# GPU0_PBIST_CFG register map
Vendor: Texas Instruments
Peripheral module from a debugger description file (folder J7ES).
Registers are 32-bit, read-write, reset 0x0 unless marked. A register's access mark holds for its fields unless they carry their own. Offsets are as the file gives them; lines under a group give offsets from that group; [hi:lo] are bit positions; {n}, {i} and the like mark numbered series; 'fields as' and 'values as' point back to an identical list; <NAME> marks a mode.

## GPU0_PBIST_CFG
{0x100+4i} GPU0_A{i} (i=0..3) — Return to the . Variable Address Registers
  [15:0] A{i} — Variable Address Register {i} (
{0x110+4i} GPU0_L{i} (i=0..3) — Return to the . Variable Loop Count Registers
  [15:0] L{i} — Variable Loop Count Register {i} (
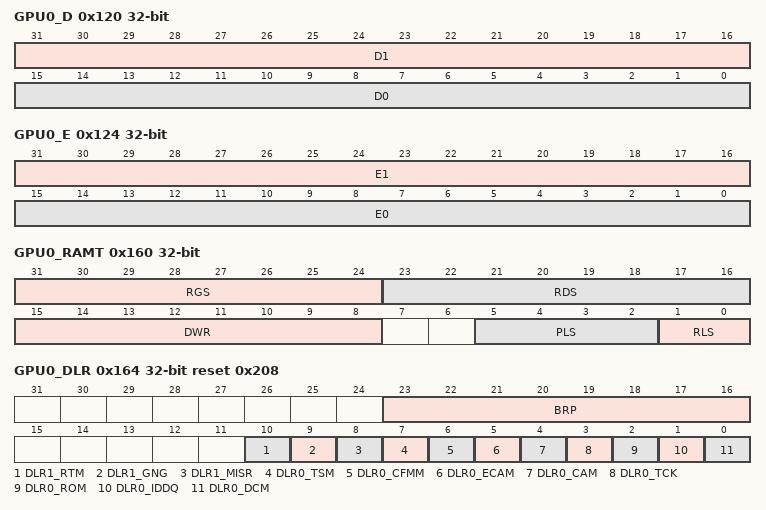
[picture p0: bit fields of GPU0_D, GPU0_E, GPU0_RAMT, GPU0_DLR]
0x120 GPU0_D — Return to the . Data Registers
  [31:16] D1 — DD1 Data Register Upper 16 (D1)
  [15:0] D0 — DD0 Data Register Lower 16 (D0)
0x124 GPU0_E — Return to the . Data Registers
  [31:16] E1 — EE1 Data Register Upper 16 (E1)
  [15:0] E0 — EE0 Data Register Lower 16 (E0)
{0x130+4i} GPU0_CA{i} (i=0..3) — Return to the . Constant Address Registers
  [15:0] CA{i} — Constant Address Register {i} (
{0x140+4i} GPU0_CL{i} (i=0..3) — Return to the . Constant Loop Count Registers
  [15:0] CL{i} — Constant Loop Count Register {i} (
{0x150+4i} GPU0_I{i} (i=0..3) — Return to the . Constant Increment Registers
  [15:0] I0 — Constant Increment Register {i} (
0x160 GPU0_RAMT — Return to the . RAM Configuration Register
  [31:24] RGS — RAM Group Select RGS
  [23:16] RDS — Return Data select RDS
  [15:8] DWR — Data Width Register DWR
  [5:2] PLS — Pipeline Latency Select
  [1:0] RLS — RAM Latency Select
0x164 GPU0_DLR reset 0x208 — Return to the . Datalogger Register
  [23:16] BRP — Datalogger 2 (BRP)
  [10] DLR1_RTM — Retention testing mode
  [9] DLR1_GNG — GO / NO-GO testing mode
  [8] DLR1_MISR — MISR testing mode (mainly for
  [7] DLR0_TSM — Time stamp mode
  [6] DLR0_CFMM — Column Fail Masking mode
  [5] DLR0_ECAM — Emulation cache access mode
  [4] DLR0_CAM — Config access mode
  [3] DLR0_TCK — TCK Gated mode
  [2] DLR0_ROM
  [1] DLR0_IDDQ — IDDQ testing mode
  [0] DLR0_DCM — Distributed Compare mode
0x168 GPU0_CMS — Return to the . Clock-Mux Select Register
  [3:0] CMS — Clock Mux Select (
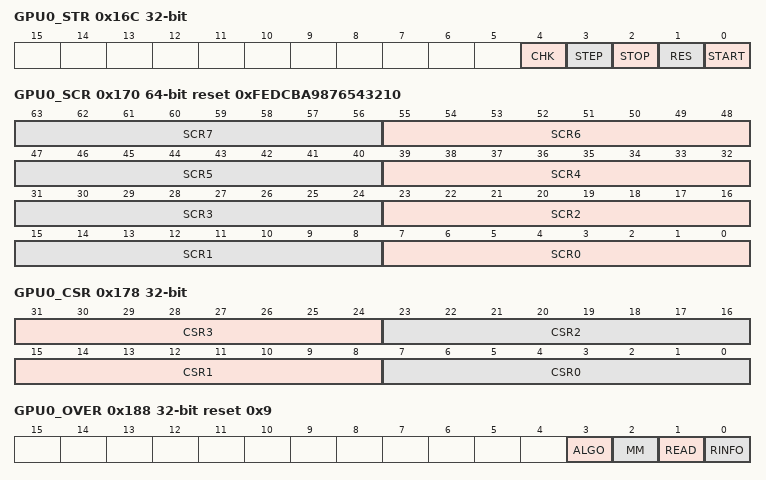
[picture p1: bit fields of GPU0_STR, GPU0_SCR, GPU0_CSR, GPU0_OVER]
0x16C GPU0_STR — Return to the . Program Control Register
  [4] CHK — Check MISR mode
  [3] STEP — Step / Step for emulation mode
  [2] STOP
  [1] RES — Resume / Emulation read
  [0] START — Start / Time Stamp mode restart
0x170 GPU0_SCR 64-bit reset 0xFEDCBA9876543210 — Return to the . Address Scrambling Register
  [8n+7:8n] SCR{n} (n=0..7) — Address Scrambling Register {n}
0x178 GPU0_CSR — Return to the . Chip Select Register
  [31:24] CSR3 — Chip Select 3 (CSR3)
  [23:16] CSR2 — Chip Select 2 (CSR2)
  [15:8] CSR1 — Chip Select 1(CSR1)
  [7:0] CSR0 — Chip Select 0 (CSR0)
0x17C GPU0_FDLY reset 0x68 — Return to the . Fail Delay Register
  [7:0] FDLY — Fail Delay (
0x180 GPU0_PACT — Return to the . Register
  [0] PACT — PBIST Activate (
0x184 GPU0_PID — Return to the . PBIST_ID Register
  [4:0] PID — PBIST ID
0x188 GPU0_OVER reset 0x9 — Return to the . Override Register
  [3] ALGO — PBIST Override Algorithm Override
  [2] MM — PBIST Override Multiple Memory
  [1] READ — PBIST Override READ Override
  [0] RINFO — PBIST Override
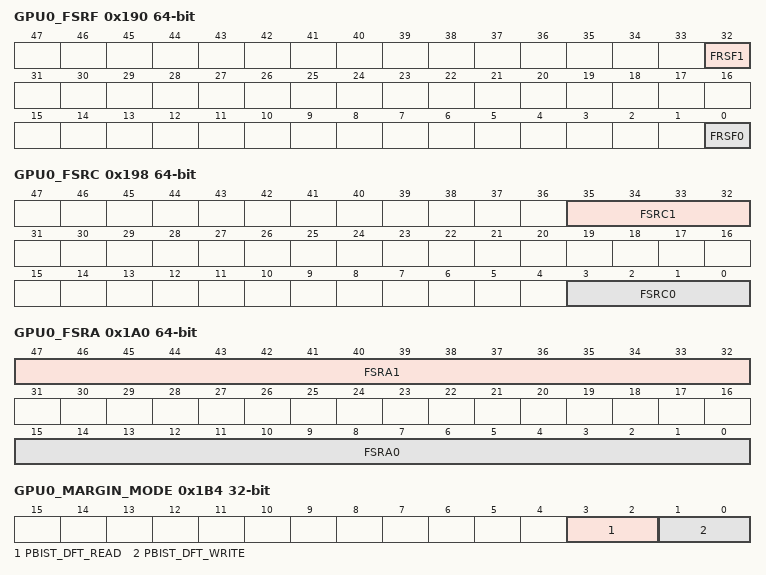
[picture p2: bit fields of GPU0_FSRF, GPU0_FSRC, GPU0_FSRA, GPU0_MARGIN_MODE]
0x190 GPU0_FSRF 64-bit ro — Return to the . Fail Status Fail Register
  [32] FRSF1 — Fail Status Fail - Port 1 (FSRF1)
  [0] FRSF0 — Fail Status Fail - Port 0 (FSRF0)
0x198 GPU0_FSRC 64-bit ro — Return to the . Fail Status Count Register
  [35:32] FSRC1 — Fail Status Count - Port 1 (FSRC1)
  [3:0] FSRC0 — Fail Status Count - Port 0 (FSRC0)
0x1A0 GPU0_FSRA 64-bit ro — Return to the . Fail Status Address Register
  [47:32] FSRA1 — Fail Status Address - Port 1 (FSRA1)
  [15:0] FSRA0 — Fail Status Address - Port 0 (FSRA0)
0x1A8 GPU0_FSRDL0 ro — Return to the . Fail Status Data Registers
  [31:0] FSRDL0 — Fail Status Data - Port 0 (
0x1B0 GPU0_FSRDL1 ro — Return to the . Fail Status Data Registers
  [31:0] FSRDL1 — Fail Status Data - Port 1 (
0x1B4 GPU0_MARGIN_MODE ro — Return to the . Fail Status Fail Register
  [3:2] PBIST_DFT_READ, [1:0] PBIST_DFT_WRITE
0x1B8 GPU0_WRENZ ro — Return to the . Fail Status Fail Register
  [1:0] WRENZ — pbist_ram_wrenz
0x1BC GPU0_PAGE_PGS ro — Return to the . Fail Status Fail Register
  [1:0] PGS — pbist_ram_pgs
0x1C0 GPU0_ROM reset 0x3 — Return to the . Mask Register
  [1:0] ROM
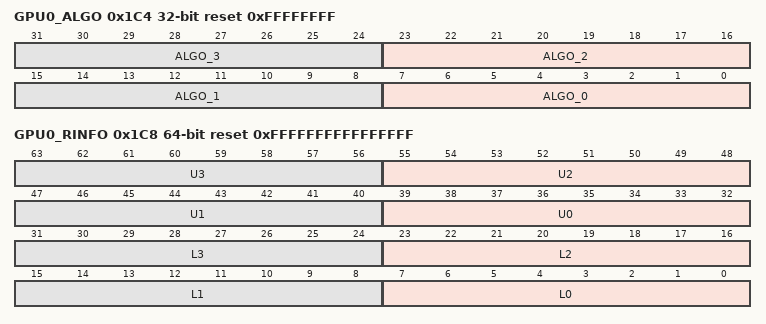
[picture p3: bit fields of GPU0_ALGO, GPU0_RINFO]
0x1C4 GPU0_ALGO reset 0xFFFFFFFF — Return to the . Algorithm Mask Register
  [8n+7:8n] ALGO_{n} (n=0..3)
0x1C8 GPU0_RINFO 64-bit reset 0xFFFFFFFFFFFFFFFF — Return to the . RAM Info Mask Register
  [8n+39:8n+32] U{n} (n=0..3) — RAM Info Mask Upper {n} (RINFOU{n})
  [8n+7:8n] L{n} (n=0..3) — RAM Info Mask Lower {n} (RINFOL{n})
